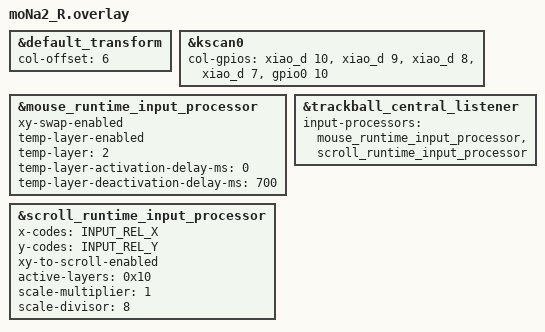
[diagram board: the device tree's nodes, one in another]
#include "moNa2.dtsi"
/* RC(row,col)の展開後に読み込み、修飾キーのRC(keycode)との衝突を避ける。 */
#include <input/processors/runtime-input-processor.dtsi>
#include <zephyr/dt-bindings/input/input-event-codes.h>

&default_transform {
    col-offset = <6>;
};

&kscan0 {
    col-gpios = <&xiao_d 10 GPIO_ACTIVE_HIGH>,
                <&xiao_d 9 GPIO_ACTIVE_HIGH>,
                <&xiao_d 8 GPIO_ACTIVE_HIGH>,
                <&xiao_d 7 GPIO_ACTIVE_HIGH>,
                <&gpio0 10 GPIO_ACTIVE_HIGH>;
};

&mouse_runtime_input_processor {
    /* Keyball39右側と同じXY入れ替えと、記号・マウス層の自動有効化。 */
    xy-swap-enabled;
    temp-layer-enabled;
    temp-layer = <2>;
    temp-layer-activation-delay-ms = <0>;
    temp-layer-deactivation-delay-ms = <700>;
};

&scroll_runtime_input_processor {
    x-codes = <INPUT_REL_X>;
    y-codes = <INPUT_REL_Y>;
    xy-to-scroll-enabled;
    active-layers = <0x10>;
    scale-multiplier = <1>;
    scale-divisor = <8>;
};

&trackball_central_listener {
    input-processors = <&mouse_runtime_input_processor &scroll_runtime_input_processor>;
};
